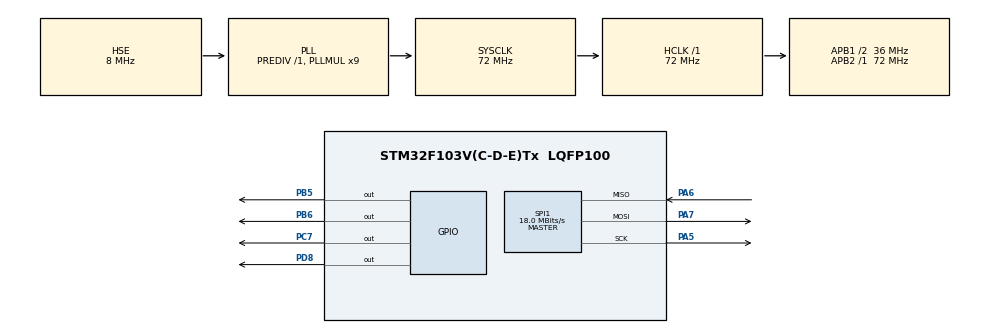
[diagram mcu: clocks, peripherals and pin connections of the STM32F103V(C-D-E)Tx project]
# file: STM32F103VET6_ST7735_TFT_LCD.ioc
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Dma.Request0=SPI1_TX
Dma.SPI1_TX.0.Direction=DMA_MEMORY_TO_PERIPH
Dma.SPI1_TX.0.Instance=DMA1_Channel3
Dma.SPI1_TX.0.MemDataAlignment=DMA_MDATAALIGN_BYTE
Dma.SPI1_TX.0.MemInc=DMA_MINC_ENABLE
Dma.SPI1_TX.0.Mode=DMA_NORMAL
Dma.SPI1_TX.0.PeriphDataAlignment=DMA_PDATAALIGN_BYTE
Dma.SPI1_TX.0.PeriphInc=DMA_PINC_DISABLE
Dma.SPI1_TX.0.Priority=DMA_PRIORITY_HIGH
Mcu.Family=STM32F1
Mcu.Name=STM32F103V(C-D-E)Tx
Mcu.Package=LQFP100
NVIC.DMA1_Channel3_IRQn=true\:0\:0\:false\:false\:true\:false\:true
NVIC.PriorityGroup=NVIC_PRIORITYGROUP_4
NVIC.SPI1_IRQn=true\:0\:0\:false\:false\:true\:true\:true
OSC_IN.Mode=HSE-External-Oscillator
OSC_IN.Signal=RCC_OSC_IN
OSC_OUT.Mode=HSE-External-Oscillator
OSC_OUT.Signal=RCC_OSC_OUT
PA13.Mode=Serial_Wire
PA13.Signal=SYS_JTMS-SWDIO
PA14.Mode=Serial_Wire
PA14.Signal=SYS_JTCK-SWCLK
PA5.Mode=Full_Duplex_Master
PA5.Signal=SPI1_SCK
PA6.Mode=Full_Duplex_Master
PA6.Signal=SPI1_MISO
PA7.Mode=Full_Duplex_Master
PA7.Signal=SPI1_MOSI
PB5.GPIO_Speed=GPIO_SPEED_FREQ_HIGH
PB5.PinState=GPIO_PIN_SET
PB5.Signal=GPIO_Output
PB6.Signal=GPIO_Output
PC7.Signal=GPIO_Output
PD8.Signal=GPIO_Output
ProjectManager.HeapSize=0x200
ProjectManager.StackSize=0x400
ProjectManager.TargetToolchain=MDK-ARM V5.27
RCC.AHBFreq_Value=72000000
RCC.APB1CLKDivider=RCC_HCLK_DIV2
RCC.APB1Freq_Value=36000000
RCC.APB1TimFreq_Value=72000000
RCC.APB2Freq_Value=72000000
RCC.APB2TimFreq_Value=72000000
RCC.HCLKFreq_Value=72000000
RCC.PLLMUL=RCC_PLL_MUL9
RCC.PLLSourceVirtual=RCC_PLLSOURCE_HSE
RCC.SYSCLKFreq_VALUE=72000000
RCC.SYSCLKSource=RCC_SYSCLKSOURCE_PLLCLK
RCC.USBFreq_Value=72000000
SPI1.BaudRatePrescaler=SPI_BAUDRATEPRESCALER_4
SPI1.CalculateBaudRate=18.0 MBits/s
SPI1.Direction=SPI_DIRECTION_2LINES
SPI1.Mode=SPI_MODE_MASTER
SPI1.VirtualType=VM_MASTER
board=custom

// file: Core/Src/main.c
/* USER CODE BEGIN Header */
/**
  ******************************************************************************
  * @file           : main.c
  * @brief          : Main program body
  ******************************************************************************
  * @attention
  *
  * <h2><center>&copy; Copyright (c) 2024 STMicroelectronics.
  * All rights reserved.</center></h2>
  *
  * This software component is licensed by ST under BSD 3-Clause license,
  * the "License"; You may not use this file except in compliance with the
  * License. You may obtain a copy of the License at:
  *                        opensource.org/licenses/BSD-3-Clause
  *
  ******************************************************************************
  */
/* USER CODE END Header */
#include "main.h"

/* USER CODE BEGIN Includes */
#include "ST7735.h"
#include "fonts.h"
#include "testing.h"
/* USER CODE END Includes */

/* USER CODE BEGIN PTD */

uint16_t matrix[94] = {0x63f4 ,0x63f4 ,0x63d4 ,0x5bd3 ,0x5bd3 ,0x5bd3 ,0x5bd3 ,0x63d4 ,0x63f4 ,0x5bd4 ,0x5bd4 ,0x63f4 ,0x6414 ,0x6415 ,0x6415 ,0x6415 ,0x6c35 ,0x6c35 ,0x6c14 ,0x6c35 ,0x6c35 ,0x6c35 ,0x6c35 ,0x6c35 ,0x6c14 ,0x6c14 ,0x6c14 ,0x6414 ,0x63f4 ,0x6414 ,0x6c14 ,0x6c35 ,0x6c55 ,0x7455 ,0x7475 ,0x7455 ,0x7475 ,0x7455 ,0x7455 ,0x7475 ,0x7475 ,0x7476 ,0x7476 ,0x7476 ,0x7c96 ,0x7c96 ,0x7c96 ,0x7c96 ,0x7cb6 ,0x7cb6 ,0x7cb6 ,0x84d7 ,0x84f7 ,0x8517 ,0x84f7 ,0x84d7 ,0x84d7 ,0x7cb6 ,0x7cb6 ,0x7c96 ,0x7c96 ,0x7c96 ,0x7cb6 ,0x7cb6 ,0x7cb6 ,0x7cb6 ,0x7cb6 ,0x7cb6 ,0x7cb6 ,0x7cb6 ,0x7cb6 ,0x7cb6 ,0x7c96 ,0x7c96 ,0x7c96 ,0x7496 ,0x7476 ,0x7475 ,0x7475 ,0x7455 ,0x7455 ,0x6c55 ,0x6c55 ,0x6c55 ,0x6c55 ,0x6c55 ,0x6c55 ,0x6c35 ,0x6c35 ,0x6c35 ,0x6c35 ,0x6c35 ,0x6c35 ,0x6c35 };
/* USER CODE END PTD */

SPI_HandleTypeDef hspi1;
DMA_HandleTypeDef hdma_spi1_tx;

void SystemClock_Config(void);
static void MX_GPIO_Init(void);
static void MX_DMA_Init(void);
static void MX_SPI1_Init(void);

int main(void)
{

  /* MCU Configuration--------------------------------------------------------*/

  /* Reset of all peripherals, Initializes the Flash interface and the Systick. */
  HAL_Init();

  /* Configure the system clock */
  SystemClock_Config();

  /* Initialize all configured peripherals */
  MX_GPIO_Init();
  MX_DMA_Init();
  MX_SPI1_Init();
  /* USER CODE BEGIN 2 */
	ST7735_Init(0);
	ST7735_SetRotation(0);
	fillScreen(BLACK);

	/* Task 1 - Write your name */
	ST7735_WriteString(0, 0, "Welcome     Back dac70r", Font_11x18, YELLOW, BLACK);
	drawXBitmap(70,70,ming,32,16,YELLOW);

	/* Task 2 - Draw a dot */
	//ST7735_DrawPixel(120,120,RED);
	//ST7735_DrawPixel(119,120,RED);
	//ST7735_DrawPixel(121,120,RED);
	//ST7735_DrawPixel(120,119,RED);
	//ST7735_DrawPixel(120,121,RED);

	//drawXBitmap(100,100,dot_matrix,8,8,RED);
	//drawBitmap(100,100,dot_matrix,8,8,RED,GREEN);
	//ST7735_DrawImagez(0,0, 128, 90, (uint16_t*)test_128x128);
	//ST7735_DrawImagez(0,0,94,120, acBrandenburg_gate_cropped[0]);
	ST7735_DrawImage(0,70, 64, 51, image_data_cat_resized);
	//ST7735_DrawImage(15, 20, 94, 120, acBrandenburg_gate_cropped_low);
	//ST7735_DrawEllipse(100,100,9,6,GREEN);
	//ST7735_DrawImage(60, 60, 64, 51, image_data_cat_resized);

	//ST7735_DrawImage(0, 0, 94, 120, acBrandenburg_gate_cropped_low);
  //testAll();
  /* USER CODE END 2 */

  /* Infinite loop */
  while (1)
  {
		//ST7735_DrawImage(15,20,94,1, matrix);
		//ST7735_DrawImage(15, 20, 94, 120, acBrandenburg_gate_cropped_low);
  }

  /* USER CODE END 3 */
}

void SystemClock_Config(void)
{
  RCC_OscInitTypeDef RCC_OscInitStruct = {0};
  RCC_ClkInitTypeDef RCC_ClkInitStruct = {0};

  /** Initializes the RCC Oscillators according to the specified parameters
  * in the RCC_OscInitTypeDef structure.
  */
  RCC_OscInitStruct.OscillatorType = RCC_OSCILLATORTYPE_HSE;
  RCC_OscInitStruct.HSEState = RCC_HSE_ON;
  RCC_OscInitStruct.HSEPredivValue = RCC_HSE_PREDIV_DIV1;
  RCC_OscInitStruct.HSIState = RCC_HSI_ON;
  RCC_OscInitStruct.PLL.PLLState = RCC_PLL_ON;
  RCC_OscInitStruct.PLL.PLLSource = RCC_PLLSOURCE_HSE;
  RCC_OscInitStruct.PLL.PLLMUL = RCC_PLL_MUL9;
  if (HAL_RCC_OscConfig(&RCC_OscInitStruct) != HAL_OK)
  {
    Error_Handler();
  }
  /** Initializes the CPU, AHB and APB buses clocks
  */
  RCC_ClkInitStruct.ClockType = RCC_CLOCKTYPE_HCLK|RCC_CLOCKTYPE_SYSCLK
                              |RCC_CLOCKTYPE_PCLK1|RCC_CLOCKTYPE_PCLK2;
  RCC_ClkInitStruct.SYSCLKSource = RCC_SYSCLKSOURCE_PLLCLK;
  RCC_ClkInitStruct.AHBCLKDivider = RCC_SYSCLK_DIV1;
  RCC_ClkInitStruct.APB1CLKDivider = RCC_HCLK_DIV2;
  RCC_ClkInitStruct.APB2CLKDivider = RCC_HCLK_DIV1;

  if (HAL_RCC_ClockConfig(&RCC_ClkInitStruct, FLASH_LATENCY_2) != HAL_OK)
  {
    Error_Handler();
  }
}

static void MX_SPI1_Init(void)
{

  /* SPI1 parameter configuration*/
  hspi1.Instance = SPI1;
  hspi1.Init.Mode = SPI_MODE_MASTER;
  hspi1.Init.Direction = SPI_DIRECTION_2LINES;
  hspi1.Init.DataSize = SPI_DATASIZE_8BIT;
  hspi1.Init.CLKPolarity = SPI_POLARITY_LOW;
  hspi1.Init.CLKPhase = SPI_PHASE_1EDGE;
  hspi1.Init.NSS = SPI_NSS_SOFT;
  hspi1.Init.BaudRatePrescaler = SPI_BAUDRATEPRESCALER_4;
  hspi1.Init.FirstBit = SPI_FIRSTBIT_MSB;
  hspi1.Init.TIMode = SPI_TIMODE_DISABLE;
  hspi1.Init.CRCCalculation = SPI_CRCCALCULATION_DISABLE;
  hspi1.Init.CRCPolynomial = 10;
  if (HAL_SPI_Init(&hspi1) != HAL_OK)
  {
    Error_Handler();
  }

}

static void MX_DMA_Init(void)
{

  /* DMA controller clock enable */
  __HAL_RCC_DMA1_CLK_ENABLE();

  /* DMA interrupt init */
  /* DMA1_Channel3_IRQn interrupt configuration */
  HAL_NVIC_SetPriority(DMA1_Channel3_IRQn, 0, 0);
  HAL_NVIC_EnableIRQ(DMA1_Channel3_IRQn);

}

static void MX_GPIO_Init(void)
{
  GPIO_InitTypeDef GPIO_InitStruct = {0};

  /* GPIO Ports Clock Enable */
  __HAL_RCC_GPIOA_CLK_ENABLE();
  __HAL_RCC_GPIOD_CLK_ENABLE();
  __HAL_RCC_GPIOC_CLK_ENABLE();
  __HAL_RCC_GPIOB_CLK_ENABLE();

  /*Configure GPIO pin Output Level */
  HAL_GPIO_WritePin(GPIOD, GPIO_PIN_8, GPIO_PIN_RESET);

  /*Configure GPIO pin Output Level */
  HAL_GPIO_WritePin(GPIOC, GPIO_PIN_7, GPIO_PIN_RESET);

  /*Configure GPIO pin Output Level */
  HAL_GPIO_WritePin(GPIOB, GPIO_PIN_5, GPIO_PIN_SET);

  /*Configure GPIO pin Output Level */
  HAL_GPIO_WritePin(GPIOB, GPIO_PIN_6, GPIO_PIN_RESET);

  /*Configure GPIO pin : PD8 */
  GPIO_InitStruct.Pin = GPIO_PIN_8;
  GPIO_InitStruct.Mode = GPIO_MODE_OUTPUT_PP;
  GPIO_InitStruct.Pull = GPIO_NOPULL;
  GPIO_InitStruct.Speed = GPIO_SPEED_FREQ_LOW;
  HAL_GPIO_Init(GPIOD, &GPIO_InitStruct);

  /*Configure GPIO pin : PC7 */
  GPIO_InitStruct.Pin = GPIO_PIN_7;
  GPIO_InitStruct.Mode = GPIO_MODE_OUTPUT_PP;
  GPIO_InitStruct.Pull = GPIO_NOPULL;
  GPIO_InitStruct.Speed = GPIO_SPEED_FREQ_LOW;
  HAL_GPIO_Init(GPIOC, &GPIO_InitStruct);

  /*Configure GPIO pin : PB5 */
  GPIO_InitStruct.Pin = GPIO_PIN_5;
  GPIO_InitStruct.Mode = GPIO_MODE_OUTPUT_PP;
  GPIO_InitStruct.Pull = GPIO_NOPULL;
  GPIO_InitStruct.Speed = GPIO_SPEED_FREQ_HIGH;
  HAL_GPIO_Init(GPIOB, &GPIO_InitStruct);

  /*Configure GPIO pin : PB6 */
  GPIO_InitStruct.Pin = GPIO_PIN_6;
  GPIO_InitStruct.Mode = GPIO_MODE_OUTPUT_PP;
  GPIO_InitStruct.Pull = GPIO_NOPULL;
  GPIO_InitStruct.Speed = GPIO_SPEED_FREQ_LOW;
  HAL_GPIO_Init(GPIOB, &GPIO_InitStruct);

}

/* USER CODE BEGIN 4
void HAL_SPI_TxCpltCallback(SPI_HandleTypeDef *hspi)
{
	HAL_GPIO_TogglePin(GPIOB,GPIO_PIN_5);
	HAL_Delay(100);
	__NOP();
}*/

/* USER CODE END 4 */

void Error_Handler(void)
{
  __disable_irq();
  while (1)
  {
  }
}

/************************ (C) COPYRIGHT STMicroelectronics *****END OF FILE****/
